# EFR32BG13P532F512GM32 register map
File version: 5.8.2
CPU: CM4 r0p1, little endian, MPU, FPU, 3 interrupt priority bits
Registers are 32-bit, read-write, reset 0x0 unless marked. A register's access mark holds for its fields unless they carry their own. Offsets are from the block's base; [hi:lo] are bit positions.

## NVIC_IABR — Nested vectored interrupt controller
Base 0xE000E300
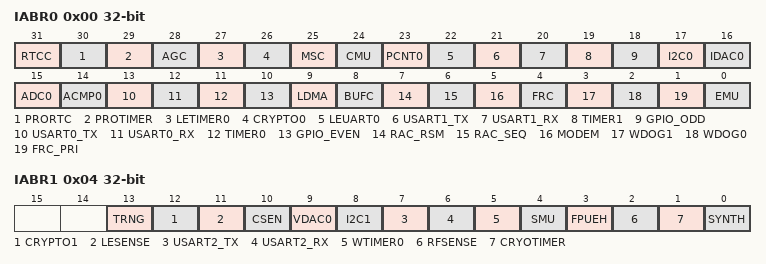
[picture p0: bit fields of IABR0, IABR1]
0x00 IABR0 — Interrupt Active bit Register 0
  [31] RTCC — RTCC Interrupt
  [30] PRORTC — PRORTC Interrupt
  [29] PROTIMER — PROTIMER Interrupt
  [28] AGC — AGC Interrupt
  [27] LETIMER0 — LETIMER0 Interrupt
  [26] CRYPTO0 — CRYPTO0 Interrupt
  [25] MSC — MSC Interrupt
  [24] CMU — CMU Interrupt
  [23] PCNT0 — PCNT0 Interrupt
  [22] LEUART0 — LEUART0 Interrupt
  [21] USART1_TX — USART1_TX Interrupt
  [20] USART1_RX — USART1_RX Interrupt
  [19] TIMER1 — TIMER1 Interrupt
  [18] GPIO_ODD — GPIO_ODD Interrupt
  [17] I2C0 — I2C0 Interrupt
  [16] IDAC0 — IDAC0 Interrupt
  [15] ADC0 — ADC0 Interrupt
  [14] ACMP0 — ACMP0 Interrupt
  [13] USART0_TX — USART0_TX Interrupt
  [12] USART0_RX — USART0_RX Interrupt
  [11] TIMER0 — TIMER0 Interrupt
  [10] GPIO_EVEN — GPIO_EVEN Interrupt
  [9] LDMA — LDMA Interrupt
  [8] BUFC — BUFC Interrupt
  [7] RAC_RSM — RAC_RSM Interrupt
  [6] RAC_SEQ — RAC_SEQ Interrupt
  [5] MODEM — MODEM Interrupt
  [4] FRC — FRC Interrupt
  [3] WDOG1 — WDOG1 Interrupt
  [2] WDOG0 — WDOG0 Interrupt
  [1] FRC_PRI — FRC_PRI Interrupt
  [0] EMU — EMU Interrupt
0x04 IABR1 — Interrupt Active bit Register 1
  [13] TRNG — TRNG Interrupt
  [12] CRYPTO1 — CRYPTO1 Interrupt
  [11] LESENSE — LESENSE Interrupt
  [10] CSEN — CSEN Interrupt
  [9] VDAC0 — VDAC0 Interrupt
  [8] I2C1 — I2C1 Interrupt
  [7] USART2_TX — USART2_TX Interrupt
  [6] USART2_RX — USART2_RX Interrupt
  [5] WTIMER0 — WTIMER0 Interrupt
  [4] SMU — SMU Interrupt
  [3] FPUEH — FPUEH Interrupt
  [2] RFSENSE — RFSENSE Interrupt
  [1] CRYOTIMER — CRYOTIMER Interrupt
  [0] SYNTH — SYNTH Interrupt

## NVIC_IP — Nested vectored interrupt controller
Base 0xE000E400
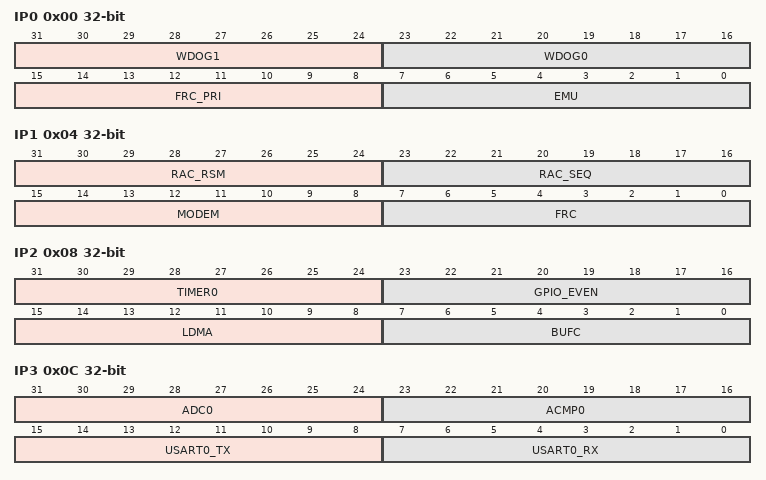
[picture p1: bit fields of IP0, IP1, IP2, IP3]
0x00 IP0 — Interrupt Priority Register 0
  [31:24] WDOG1 — WDOG1 Interrupt
  [23:16] WDOG0 — WDOG0 Interrupt
  [15:8] FRC_PRI — FRC_PRI Interrupt
  [7:0] EMU — EMU Interrupt
0x04 IP1 — Interrupt Priority Register 1
  [31:24] RAC_RSM — RAC_RSM Interrupt
  [23:16] RAC_SEQ — RAC_SEQ Interrupt
  [15:8] MODEM — MODEM Interrupt
  [7:0] FRC — FRC Interrupt
0x08 IP2 — Interrupt Priority Register 2
  [31:24] TIMER0 — TIMER0 Interrupt
  [23:16] GPIO_EVEN — GPIO_EVEN Interrupt
  [15:8] LDMA — LDMA Interrupt
  [7:0] BUFC — BUFC Interrupt
0x0C IP3 — Interrupt Priority Register 3
  [31:24] ADC0 — ADC0 Interrupt
  [23:16] ACMP0 — ACMP0 Interrupt
  [15:8] USART0_TX — USART0_TX Interrupt
  [7:0] USART0_RX — USART0_RX Interrupt
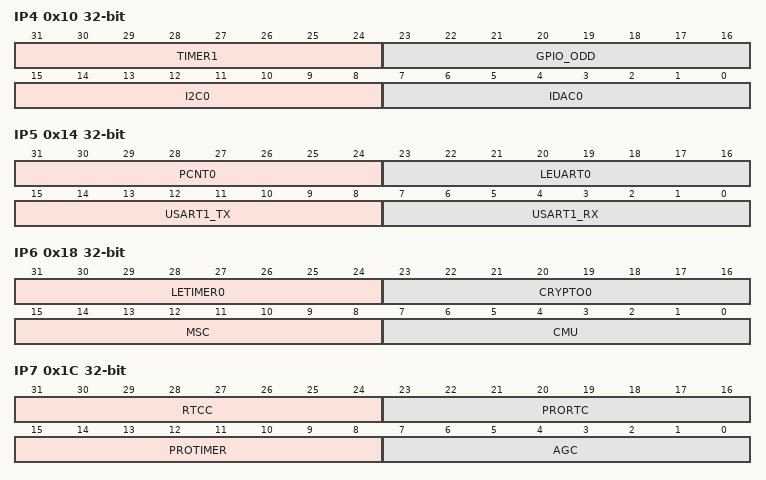
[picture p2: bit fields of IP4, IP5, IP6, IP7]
0x10 IP4 — Interrupt Priority Register 4
  [31:24] TIMER1 — TIMER1 Interrupt
  [23:16] GPIO_ODD — GPIO_ODD Interrupt
  [15:8] I2C0 — I2C0 Interrupt
  [7:0] IDAC0 — IDAC0 Interrupt
0x14 IP5 — Interrupt Priority Register 5
  [31:24] PCNT0 — PCNT0 Interrupt
  [23:16] LEUART0 — LEUART0 Interrupt
  [15:8] USART1_TX — USART1_TX Interrupt
  [7:0] USART1_RX — USART1_RX Interrupt
0x18 IP6 — Interrupt Priority Register 6
  [31:24] LETIMER0 — LETIMER0 Interrupt
  [23:16] CRYPTO0 — CRYPTO0 Interrupt
  [15:8] MSC — MSC Interrupt
  [7:0] CMU — CMU Interrupt
0x1C IP7 — Interrupt Priority Register 7
  [31:24] RTCC — RTCC Interrupt
  [23:16] PRORTC — PRORTC Interrupt
  [15:8] PROTIMER — PROTIMER Interrupt
  [7:0] AGC — AGC Interrupt
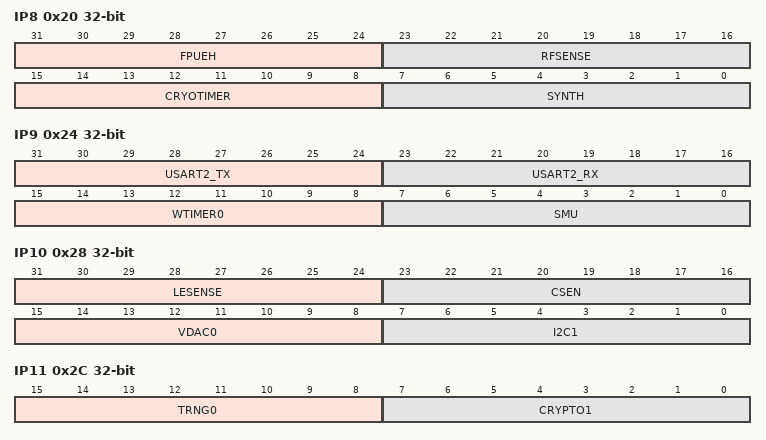
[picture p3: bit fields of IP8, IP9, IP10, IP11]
0x20 IP8 — Interrupt Priority Register 8
  [31:24] FPUEH — FPUEH Interrupt
  [23:16] RFSENSE — RFSENSE Interrupt
  [15:8] CRYOTIMER — CRYOTIMER Interrupt
  [7:0] SYNTH — SYNTH Interrupt
0x24 IP9 — Interrupt Priority Register 9
  [31:24] USART2_TX — USART2_TX Interrupt
  [23:16] USART2_RX — USART2_RX Interrupt
  [15:8] WTIMER0 — WTIMER0 Interrupt
  [7:0] SMU — SMU Interrupt
0x28 IP10 — Interrupt Priority Register 10
  [31:24] LESENSE — LESENSE Interrupt
  [23:16] CSEN — CSEN Interrupt
  [15:8] VDAC0 — VDAC0 Interrupt
  [7:0] I2C1 — I2C1 Interrupt
0x2C IP11 — Interrupt Priority Register 11
  [15:8] TRNG0 — TRNG0 Interrupt
  [7:0] CRYPTO1 — CRYPTO1 Interrupt

## NVIC_STIR — Nested vectored interrupt controller
Base 0xE000EF00
0x00 STIR wo — Software trigger interrupt register
  [8:0] INTID — Software generated interrupt ID

## FPU_CPACR — Floating point unit CPACR
Base 0xE000ED88
0x00 CPACR — Coprocessor access control register
  [23:20] CP

## SCB_ACTRL — System control block ACTLR
Base 0xE000E008
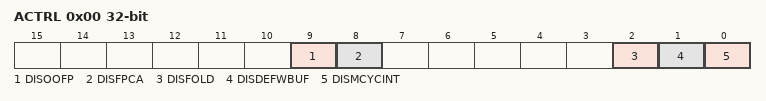
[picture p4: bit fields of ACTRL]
0x00 ACTRL — Auxiliary control register
  [9] DISOOFP, [8] DISFPCA, [2] DISFOLD, [1] DISDEFWBUF, [0] DISMCYCINT
